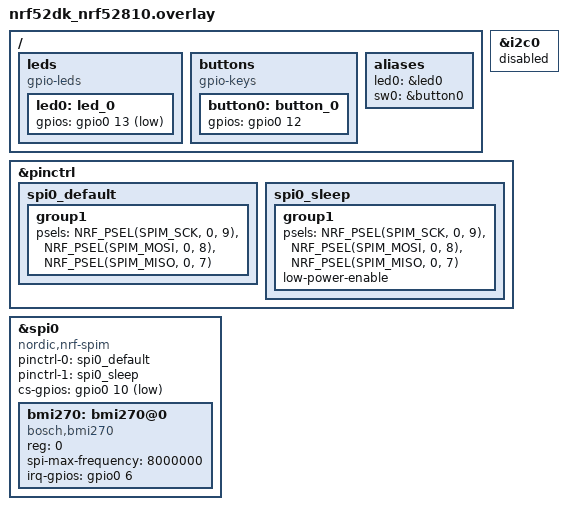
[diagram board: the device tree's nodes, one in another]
&i2c0 {
    status = "disabled";
};

&pinctrl {
    spi0_default: spi0_default {
        group1 {
            psels = <NRF_PSEL(SPIM_SCK, 0, 9)>,
                    <NRF_PSEL(SPIM_MOSI, 0, 8)>,
                    <NRF_PSEL(SPIM_MISO, 0, 7)>;
        };
    };

    spi0_sleep: spi0_sleep {
        group1 {
            psels = <NRF_PSEL(SPIM_SCK, 0, 9)>,
                    <NRF_PSEL(SPIM_MOSI, 0, 8)>,
                    <NRF_PSEL(SPIM_MISO, 0, 7)>;
            low-power-enable;
        };
    };
};

&spi0 {
    compatible = "nordic,nrf-spim";
    status = "okay";
    pinctrl-0 = <&spi0_default>;
    pinctrl-1 = <&spi0_sleep>;
    pinctrl-names = "default", "sleep";
    cs-gpios = <&gpio0 10 GPIO_ACTIVE_LOW>;

    bmi270: bmi270@0 {
        compatible = "bosch,bmi270";
        reg = <0>;
        spi-max-frequency = <8000000>;
        irq-gpios = <&gpio0 6 GPIO_ACTIVE_HIGH>;
    };
};

/ {
    leds {
        compatible = "gpio-leds";
        led0: led_0 {
            gpios = <&gpio0 13 (GPIO_ACTIVE_LOW | GPIO_OPEN_DRAIN)>;
        };
    };

    buttons {
        compatible = "gpio-keys";
        button0: button_0 {
            gpios = <&gpio0 12 (GPIO_ACTIVE_HIGH | GPIO_PULL_DOWN)>;
        };
    };

    aliases {
        led0 = &led0;
        sw0 = &button0;
    };
};
